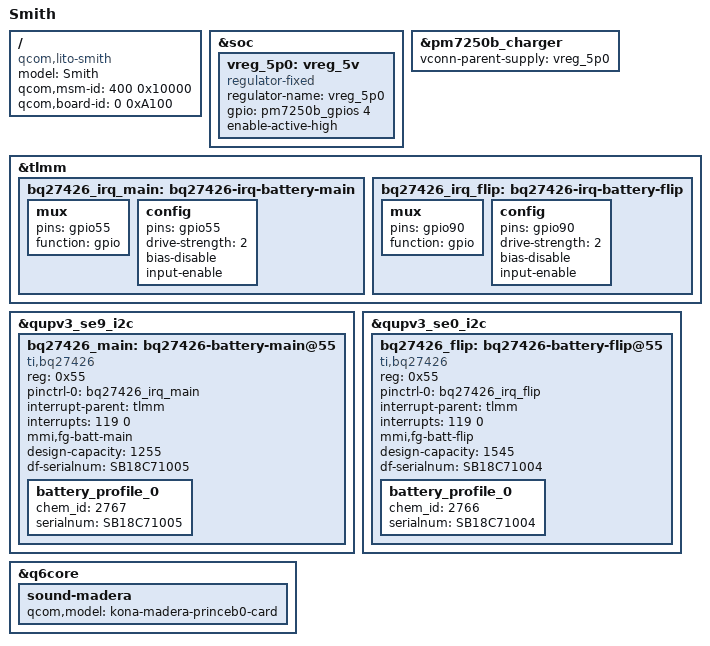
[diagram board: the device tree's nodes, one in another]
/* Copyright (c) 2019-2020, The Linux Foundation. All rights reserved.
 *
 * This program is free software; you can redistribute it and/or modify
 * it under the terms of the GNU General Public License version 2 and
 * only version 2 as published by the Free Software Foundation.
 *
 * This program is distributed in the hope that it will be useful,
 * but WITHOUT ANY WARRANTY; without even the implied warranty of
 * MERCHANTABILITY or FITNESS FOR A PARTICULAR PURPOSE.  See the
 * GNU General Public License for more details.
 */

/dts-v1/;
/plugin/;

#include "lito-smith-common-overlay.dtsi"

/ {
	model = "Smith";
	compatible = "qcom,lito-smith", "qcom,lito-moto", "qcom,lito";
	qcom,msm-id = <400 0x10000>;
	qcom,board-id = <0 0xA100>;
};

/*
 * Smith HW rev EVT1 specific changes go here
 */

&soc {
	vreg_5p0: vreg_5v {
		compatible = "regulator-fixed";
		regulator-name = "vreg_5p0";
		gpio = <&pm7250b_gpios 4 0>;
		enable-active-high;
	};
};

&pm7250b_charger {
	vconn-parent-supply = <&vreg_5p0>;
};

&tlmm{
	bq27426_irq_main: bq27426-irq-battery-main {
		mux {
			pins = "gpio55";
			function = "gpio";
		};

		config {
			pins = "gpio55";
			drive-strength = <2>; /* 2 MA */
			bias-disable;
			input-enable;
		};
	};

};

&qupv3_se9_i2c {
	bq27426_main: bq27426-battery-main@55 {
		compatible = "ti,bq27426";
		reg = <0x55>;
		status = "okay";
		pinctrl-names = "default";
		pinctrl-0 = <&bq27426_irq_main>;
		interrupt-parent = <&tlmm>;
		interrupts = <119 0>;
		interrupt-names = "bq27426_irq";
		mmi,fg-batt-main;
		design-capacity = <1255>;
		df-serialnum = "SB18C71005";
		battery_profile_0 {
			chem_id = <2767>;
			serialnum = "SB18C71005";
		};
	};
};

&tlmm{
	bq27426_irq_flip: bq27426-irq-battery-flip {
		mux {
			pins = "gpio90";
			function = "gpio";
		};

		config {
			pins = "gpio90";
			drive-strength = <2>; /* 2 MA */
			bias-disable;
			input-enable;
		};
	};

};

&qupv3_se0_i2c {
	bq27426_flip: bq27426-battery-flip@55 {
		compatible = "ti,bq27426";
		reg = <0x55>;
		status = "okay";
		pinctrl-names = "default";
		pinctrl-0 = <&bq27426_irq_flip>;
		interrupt-parent = <&tlmm>;
		interrupts = <119 0>;
		interrupt-names = "bq27426_irq";
		mmi,fg-batt-flip;
		design-capacity = <1545>;
		df-serialnum = "SB18C71004";
		battery_profile_0 {
			chem_id = <2766>;
			serialnum = "SB18C71004";
		};
	};
};

&q6core {
	sound-madera {
		qcom,model = "kona-madera-princeb0-card";
	};
};
